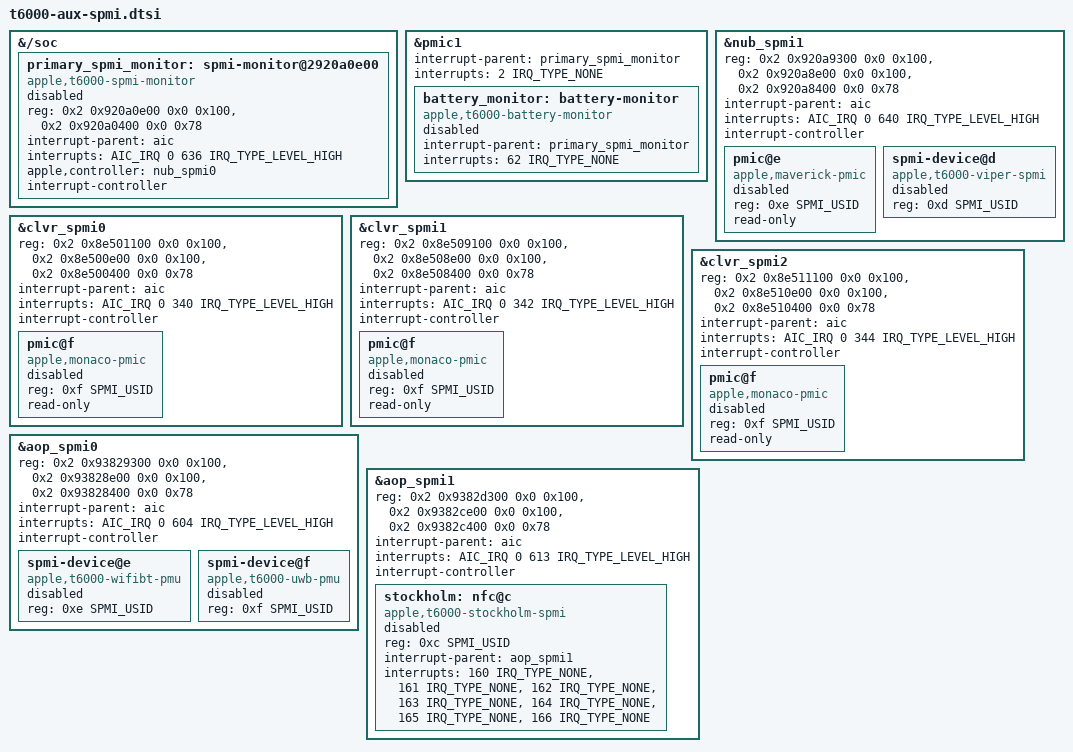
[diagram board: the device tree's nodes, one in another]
// SPDX-License-Identifier: GPL-2.0+ OR MIT
/* Disabled auxiliary SPMI resources; primary polled PMIC access is retained. */

&{/soc} {
	primary_spmi_monitor: spmi-monitor@2920a0e00 {
		compatible = "apple,t6000-spmi-monitor", "apple,spmi-monitor";
		reg = <0x2 0x920a0e00 0x0 0x100>,
		      <0x2 0x920a0400 0x0 0x78>;
		interrupt-parent = <&aic>;
		interrupts = <AIC_IRQ 0 636 IRQ_TYPE_LEVEL_HIGH>;
		apple,controller = <&nub_spmi0>;
		interrupt-controller;
		#interrupt-cells = <2>;
		#address-cells = <0>;
		status = "disabled";
	};
};

&pmic1 {
	battery_monitor: battery-monitor {
		compatible = "apple,t6000-battery-monitor", "apple,battery-monitor";
		interrupt-parent = <&primary_spmi_monitor>;
		interrupts = <62 IRQ_TYPE_NONE>;
		status = "disabled";
	};
};

&nub_spmi1 {
	reg = <0x2 0x920a9300 0x0 0x100>,
	      <0x2 0x920a8e00 0x0 0x100>,
	      <0x2 0x920a8400 0x0 0x78>;
	interrupt-parent = <&aic>;
	interrupts = <AIC_IRQ 0 640 IRQ_TYPE_LEVEL_HIGH>;
	interrupt-controller;
	#interrupt-cells = <2>;
	pmic@e {
		compatible = "apple,maverick-pmic", "apple,spmi-nvmem";
		reg = <0xe SPMI_USID>;
		read-only;
		status = "disabled";
	};
	spmi-device@d {
		compatible = "apple,t6000-viper-spmi", "apple,viper-spmi";
		reg = <0xd SPMI_USID>;
		status = "disabled";
	};
};

&clvr_spmi0 {
	reg = <0x2 0x8e501100 0x0 0x100>,
	      <0x2 0x8e500e00 0x0 0x100>,
	      <0x2 0x8e500400 0x0 0x78>;
	interrupt-parent = <&aic>;
	interrupts = <AIC_IRQ 0 340 IRQ_TYPE_LEVEL_HIGH>;
	interrupt-controller;
	#interrupt-cells = <2>;
	pmic@f {
		compatible = "apple,monaco-pmic", "apple,spmi-nvmem";
		reg = <0xf SPMI_USID>;
		read-only;
		status = "disabled";
	};
};

&clvr_spmi1 {
	reg = <0x2 0x8e509100 0x0 0x100>,
	      <0x2 0x8e508e00 0x0 0x100>,
	      <0x2 0x8e508400 0x0 0x78>;
	interrupt-parent = <&aic>;
	interrupts = <AIC_IRQ 0 342 IRQ_TYPE_LEVEL_HIGH>;
	interrupt-controller;
	#interrupt-cells = <2>;
	pmic@f {
		compatible = "apple,monaco-pmic", "apple,spmi-nvmem";
		reg = <0xf SPMI_USID>;
		read-only;
		status = "disabled";
	};
};

&clvr_spmi2 {
	reg = <0x2 0x8e511100 0x0 0x100>,
	      <0x2 0x8e510e00 0x0 0x100>,
	      <0x2 0x8e510400 0x0 0x78>;
	interrupt-parent = <&aic>;
	interrupts = <AIC_IRQ 0 344 IRQ_TYPE_LEVEL_HIGH>;
	interrupt-controller;
	#interrupt-cells = <2>;
	pmic@f {
		compatible = "apple,monaco-pmic", "apple,spmi-nvmem";
		reg = <0xf SPMI_USID>;
		read-only;
		status = "disabled";
	};
};

&aop_spmi0 {
	reg = <0x2 0x93829300 0x0 0x100>,
	      <0x2 0x93828e00 0x0 0x100>,
	      <0x2 0x93828400 0x0 0x78>;
	interrupt-parent = <&aic>;
	interrupts = <AIC_IRQ 0 604 IRQ_TYPE_LEVEL_HIGH>;
	interrupt-controller;
	#interrupt-cells = <2>;
	spmi-device@e {
		compatible = "apple,t6000-wifibt-pmu", "apple,radio-pmu";
		reg = <0xe SPMI_USID>;
		status = "disabled";
	};
	spmi-device@f {
		compatible = "apple,t6000-uwb-pmu", "apple,radio-pmu";
		reg = <0xf SPMI_USID>;
		status = "disabled";
	};
};

&aop_spmi1 {
	reg = <0x2 0x9382d300 0x0 0x100>,
	      <0x2 0x9382ce00 0x0 0x100>,
	      <0x2 0x9382c400 0x0 0x78>;
	interrupt-parent = <&aic>;
	interrupts = <AIC_IRQ 0 613 IRQ_TYPE_LEVEL_HIGH>;
	interrupt-controller;
	#interrupt-cells = <2>;
	stockholm: nfc@c {
		compatible = "apple,t6000-stockholm-spmi", "apple,stockholm-spmi";
		reg = <0xc SPMI_USID>;
		interrupt-parent = <&aop_spmi1>;
		interrupts = <160 IRQ_TYPE_NONE>,
			     <161 IRQ_TYPE_NONE>,
			     <162 IRQ_TYPE_NONE>,
			     <163 IRQ_TYPE_NONE>,
			     <164 IRQ_TYPE_NONE>,
			     <165 IRQ_TYPE_NONE>,
			     <166 IRQ_TYPE_NONE>;
		status = "disabled";
	};
};


&pmic1 {
	interrupt-parent = <&primary_spmi_monitor>;
	interrupts = <2 IRQ_TYPE_NONE>;
};
